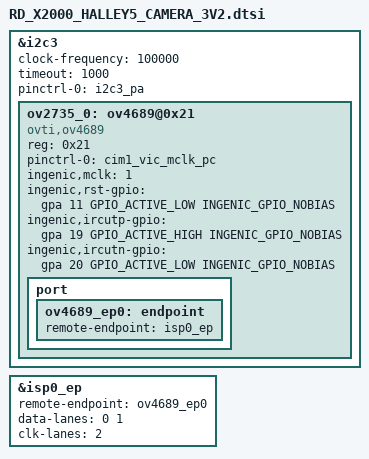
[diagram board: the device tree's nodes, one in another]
&i2c3 {
	status = "okay";
	clock-frequency = <100000>;
	timeout = <1000>;
	pinctrl-names = "default";
	pinctrl-0 = <&i2c3_pa>;

	ov2735_0:ov4689@0x21 {
		status = "ok";
		compatible = "ovti,ov4689";
		reg = <0x21>;
		pinctrl-names = "default";
		pinctrl-0 = <&cim1_vic_mclk_pc>;

		ingenic,mclk = <1>;
		ingenic,rst-gpio = <&gpa 11 GPIO_ACTIVE_LOW INGENIC_GPIO_NOBIAS>;
		ingenic,ircutp-gpio = <&gpa 19 GPIO_ACTIVE_HIGH INGENIC_GPIO_NOBIAS>;
		ingenic,ircutn-gpio = <&gpa 20 GPIO_ACTIVE_LOW INGENIC_GPIO_NOBIAS>;

		port {
			ov4689_ep0:endpoint {
				remote-endpoint = <&isp0_ep>;
			};
		};
	};
};


&isp0_ep {
	remote-endpoint = <&ov4689_ep0>;
	data-lanes = <0 1>;
	clk-lanes = <2>;
};

